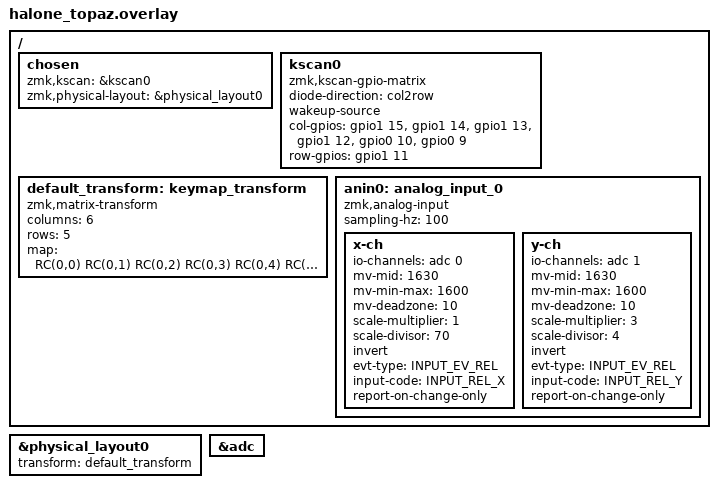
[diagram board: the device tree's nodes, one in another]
#include <dt-bindings/zmk/matrix_transform.h>
#include "halone_topaz-layouts.dtsi"
#include <zephyr/dt-bindings/input/input-event-codes.h>

&physical_layout0 {
    transform = <&default_transform>;
};

&adc {
	status = "okay";
};

/ {
    chosen {
        zmk,kscan = &kscan0;
        zmk,physical-layout = &physical_layout0;
    };

    kscan0: kscan0 {
        compatible = "zmk,kscan-gpio-matrix";
        diode-direction = "col2row";
        wakeup-source;

        col-gpios
            = <&gpio1 15 GPIO_ACTIVE_HIGH>
            , <&gpio1 14 GPIO_ACTIVE_HIGH>
            , <&gpio1 13 GPIO_ACTIVE_HIGH>
            , <&gpio1 12 GPIO_ACTIVE_HIGH>
            , <&gpio0 10 GPIO_ACTIVE_HIGH>
            , <&gpio0 9 GPIO_ACTIVE_HIGH>
            ;
        
        row-gpios
            = <&gpio1 11 (GPIO_ACTIVE_HIGH | GPIO_PULL_DOWN)>
            ;
    };

    default_transform: keymap_transform {
        compatible = "zmk,matrix-transform";
        columns = <6>;
        rows = <5>;
        map = <
            RC(0,0)  RC(0,1)  RC(0,2)  RC(0,3)  RC(0,4)  RC(0,5)
        >;
    };

	anin0: analog_input_0 {
		compatible = "zmk,analog-input";
		sampling-hz = <100>;
		x-ch {
			io-channels = <&adc 0>;
			mv-mid = <1630>;
			mv-min-max = <1600>;
			mv-deadzone = <10>;
			scale-multiplier = <1>;
			scale-divisor = <70>;
			invert;
			evt-type = <INPUT_EV_REL>;
			input-code = <INPUT_REL_X>;
			report-on-change-only;
		};
		y-ch {
			io-channels = <&adc 1>;
			mv-mid = <1630>;
			mv-min-max = <1600>;
			mv-deadzone = <10>;
			scale-multiplier = <3>;
			scale-divisor = <4>;
			invert;
			evt-type = <INPUT_EV_REL>;
			input-code = <INPUT_REL_Y>;
			report-on-change-only;
		};
	};
};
